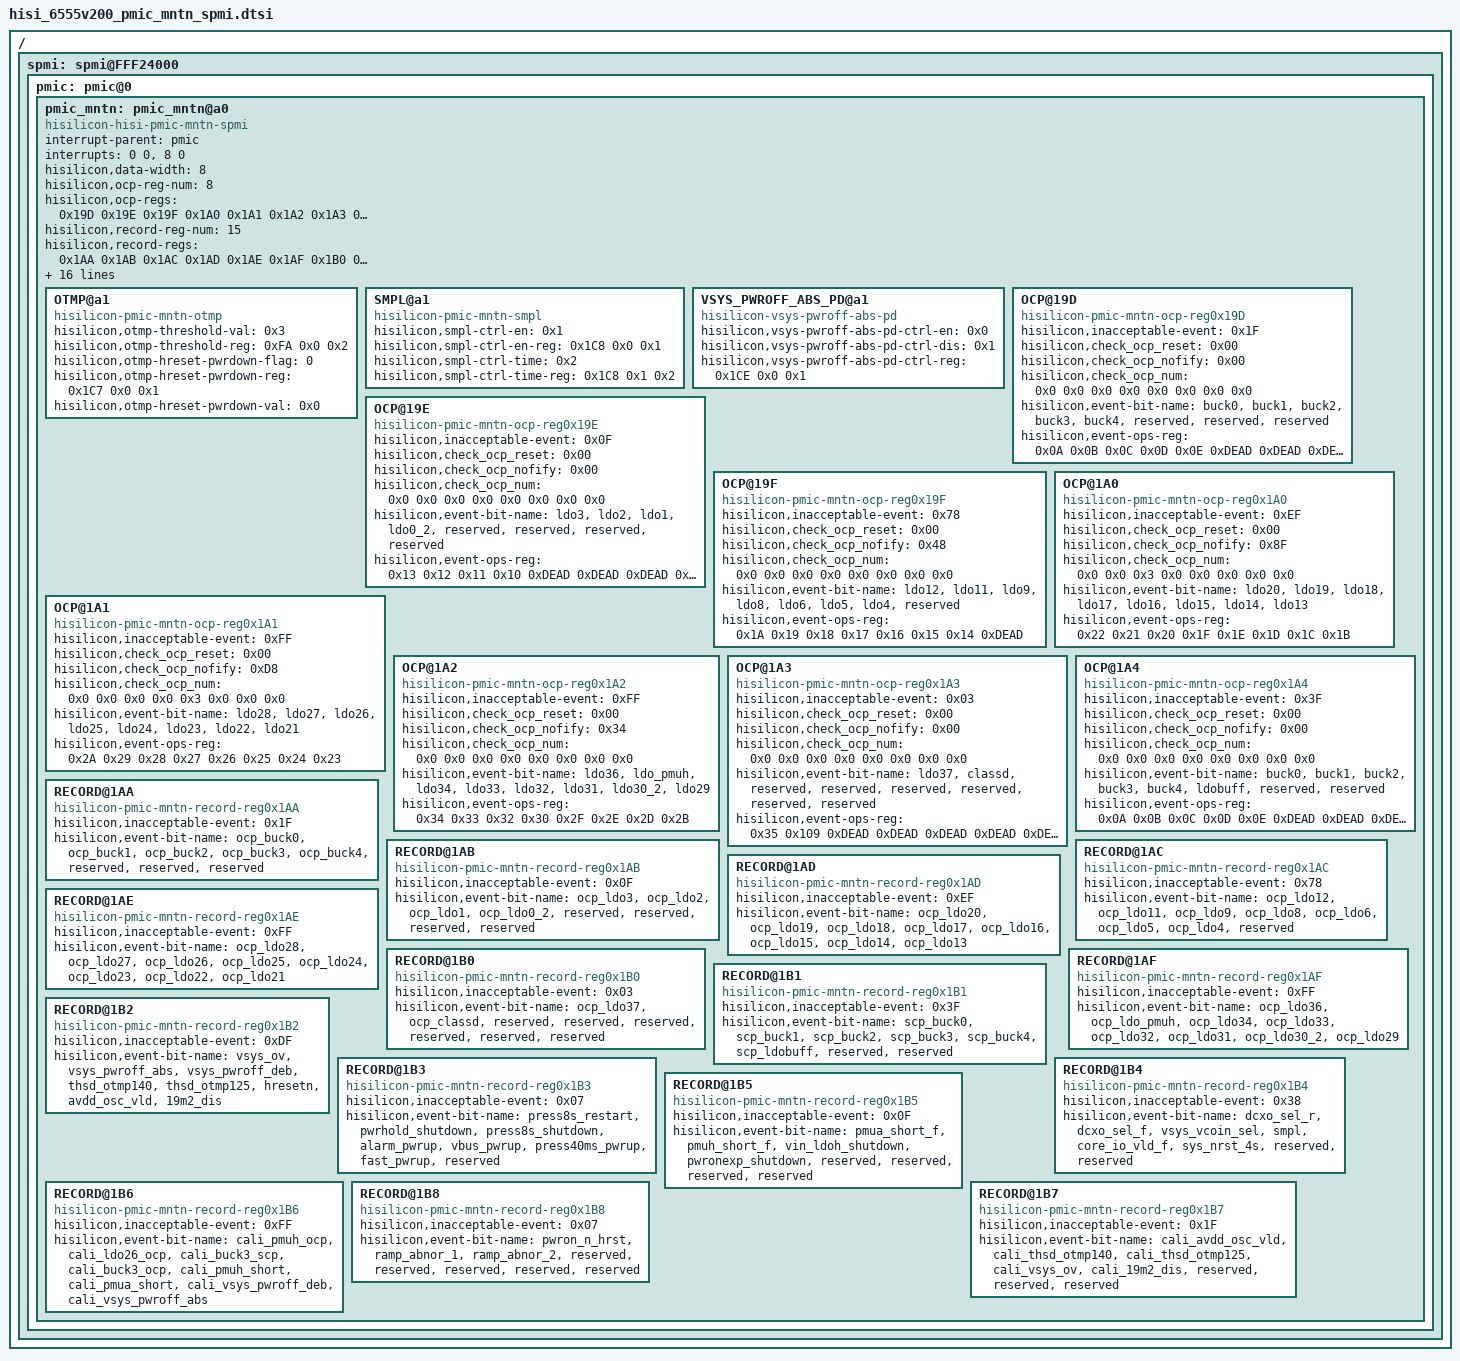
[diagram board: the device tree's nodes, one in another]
/******************************************************************************

                  版权所有 (C), 2001-2011, 华为技术有限公司

 ******************************************************************************

  This is an AUTO GENERATED file ! DON'T MODIFY MANUAL!
  文 件 名   : %(filename)s
  生成日期   : %(year)d年%(month)d月%(day)d日

******************************************************************************/

/ {
	spmi: spmi@FFF24000 {
		pmic: pmic@0 {
			pmic_mntn: pmic_mntn@a0 {
				compatible = "hisilicon-hisi-pmic-mntn-spmi";
				interrupt-parent = <&pmic>;
				interrupts = <0 0>, <8 0>;
				interrupt-names = "otmp", "ocp";
				hisilicon,data-width = <8>;
				hisilicon,ocp-reg-num = <8>;
				hisilicon,ocp-regs = <0x19D 0x19E 0x19F 0x1A0 0x1A1 0x1A2 0x1A3 0x1A4>;
				hisilicon,record-reg-num = <15>;
				hisilicon,record-regs = <0x1AA 0x1AB 0x1AC 0x1AD 0x1AE 0x1AF 0x1B0 0x1B1 0x1B2 0x1B3 0x1B4 0x1B5 0x1B6 0x1B7 0x1B8>;
				hisilicon,ocp-error-dmd-offset-number = <64>;
				hisilicon,ocp-error-dmd-offset = <
							7  6  5  4  3  99 99 99
							15 0  1  2  99 99 99 99
							23 8  10 11 50 13 14 99
							16 17 59 18 19 20 21 22
							24 25 26 27 28 29 30 31
							51 60 34 35 36 37 38 39
							61 32 99 99 99 99 99 99
							44 43 42 41 40 58 99 99
							>;
				/* this para is up to PDU, for different products may have different values */
				hisilicon,dsm-record-regs-mask = <0xFF 0xFF 0xFF 0xFF 0xFF 0xFF 0xFF 0xFF 0x00 0x00 0x00 0x00 0x00 0x00 0x00>;
				/* this para should be consistent with inacceptable-event when ocp happened */
				hisilicon,dsm-ocp-reset-mask = <0x1F 0x0F 0x78 0xEF 0xFF 0xFF 0x03 0x3F 0xFF 0xFF 0xFF 0xFF 0xFF 0xFF 0xFF>;
				hisilicon,ocp-mold-set-switch = <0>;
				hisilicon,ocp-ctrl-num = <14>;
				hisilicon,ocp-ctrl-regs = <0xDD 0xDE 0xDF 0xE0 0xE1 0xE2 0xE3 0xE4 0xE5 0xE6 0xE7 0xE8 0xE9 0xEA>;
				hisilicon,ocp-ctrl-value = <0xF7 0x03 0xDD 0x7D 0x55 0x75 0x55 0x75 0xF7 0x55 0x1F 0x07 0xF7 0x03>;
				hisilicon,pmu-record-reg-num = <7>;
				hisilicon,pmu-record-regs = <0x0EC 0x0ED 0x40 0x42 0x43 0x45 0x47>;

				OTMP@a1 {
					compatible = "hisilicon-pmic-mntn-otmp";
					/*otmp threshold value: 0x0->95, 0x1->105, 0x2->115, 0x3->125*/
					hisilicon,otmp-threshold-val = <0x3>;
					hisilicon,otmp-threshold-reg = <0xFA 0x0 0x2>;
					/*chip bug:do cold reset if pwrdown-flag == 1 && pwrdown-val == 0x0;do hot reset if pwrdown-flag == 0*/
					hisilicon,otmp-hreset-pwrdown-flag = <0>;
					hisilicon,otmp-hreset-pwrdown-reg = <0x1C7 0x0 0x1>;
					hisilicon,otmp-hreset-pwrdown-val = <0x0>;
				};

				SMPL@a1 {
					compatible = "hisilicon-pmic-mntn-smpl";
					hisilicon,smpl-ctrl-en = <0x1>;
					hisilicon,smpl-ctrl-en-reg = <0x1C8 0x0 0x1>;
					/*smpl ctrl time: 0x0->0.5s, 0x1->1.0s, 0x2->1.5s, 0x3->2.0s*/
					hisilicon,smpl-ctrl-time = <0x2>;
					hisilicon,smpl-ctrl-time-reg = <0x1C8 0x1 0x2>;
				};

				VSYS_PWROFF_ABS_PD@a1 {
					compatible = "hisilicon-vsys-pwroff-abs-pd";
					hisilicon,vsys-pwroff-abs-pd-ctrl-en = <0x0>;
					hisilicon,vsys-pwroff-abs-pd-ctrl-dis = <0x1>;
					hisilicon,vsys-pwroff-abs-pd-ctrl-reg = <0x1CE 0x0 0x1>;
				};

				OCP@19D {
					compatible = "hisilicon-pmic-mntn-ocp-reg0x19D";
					hisilicon,inacceptable-event = <0x1F>;
					hisilicon,check_ocp_reset = <0x00>;
					hisilicon,check_ocp_nofify = <0x00>;
					hisilicon,check_ocp_num = <0x0 0x0 0x0 0x0 0x0 0x0 0x0 0x0>;
					hisilicon,event-bit-name = "buck0","buck1","buck2","buck3","buck4","reserved","reserved","reserved";
					hisilicon,event-ops-reg = <0x0A 0x0B 0x0C 0x0D 0x0E 0xDEAD 0xDEAD 0xDEAD>;
				};

				OCP@19E {
					compatible = "hisilicon-pmic-mntn-ocp-reg0x19E";
					hisilicon,inacceptable-event = <0x0F>;
					hisilicon,check_ocp_reset = <0x00>;
					hisilicon,check_ocp_nofify = <0x00>;
					hisilicon,check_ocp_num = <0x0 0x0 0x0 0x0 0x0 0x0 0x0 0x0>;
					hisilicon,event-bit-name = "ldo3","ldo2","ldo1","ldo0_2","reserved","reserved","reserved","reserved";
					hisilicon,event-ops-reg = <0x13 0x12 0x11 0x10 0xDEAD 0xDEAD 0xDEAD 0xDEAD>;
				};

				OCP@19F {
					compatible = "hisilicon-pmic-mntn-ocp-reg0x19F";
					hisilicon,inacceptable-event = <0x78>;
					hisilicon,check_ocp_reset = <0x00>;
					hisilicon,check_ocp_nofify = <0x48>;
					hisilicon,check_ocp_num = <0x0 0x0 0x0 0x0 0x0 0x0 0x0 0x0>;
					hisilicon,event-bit-name = "ldo12","ldo11","ldo9","ldo8","ldo6","ldo5","ldo4","reserved";
					hisilicon,event-ops-reg = <0x1A 0x19 0x18 0x17 0x16 0x15 0x14 0xDEAD>;
				};

				OCP@1A0 {
					compatible = "hisilicon-pmic-mntn-ocp-reg0x1A0";
					hisilicon,inacceptable-event = <0xEF>;
					hisilicon,check_ocp_reset = <0x00>;
					hisilicon,check_ocp_nofify = <0x8F>;
					hisilicon,check_ocp_num = <0x0 0x0 0x3 0x0 0x0 0x0 0x0 0x0>;
					hisilicon,event-bit-name = "ldo20","ldo19","ldo18","ldo17","ldo16","ldo15","ldo14","ldo13";
					hisilicon,event-ops-reg = <0x22 0x21 0x20 0x1F 0x1E 0x1D 0x1C 0x1B>;
				};

				OCP@1A1 {
					compatible = "hisilicon-pmic-mntn-ocp-reg0x1A1";
					hisilicon,inacceptable-event = <0xFF>;
					hisilicon,check_ocp_reset = <0x00>;
					hisilicon,check_ocp_nofify = <0xD8>;
					hisilicon,check_ocp_num = <0x0 0x0 0x0 0x0 0x3 0x0 0x0 0x0>;
					hisilicon,event-bit-name = "ldo28","ldo27","ldo26","ldo25","ldo24","ldo23","ldo22","ldo21";
					hisilicon,event-ops-reg = <0x2A 0x29 0x28 0x27 0x26 0x25 0x24 0x23>;
				};

				OCP@1A2 {
					compatible = "hisilicon-pmic-mntn-ocp-reg0x1A2";
					hisilicon,inacceptable-event = <0xFF>;
					hisilicon,check_ocp_reset = <0x00>;
					hisilicon,check_ocp_nofify = <0x34>;
					hisilicon,check_ocp_num = <0x0 0x0 0x0 0x0 0x0 0x0 0x0 0x0>;
					hisilicon,event-bit-name = "ldo36","ldo_pmuh","ldo34","ldo33","ldo32","ldo31","ldo30_2","ldo29";
					hisilicon,event-ops-reg = <0x34 0x33 0x32 0x30 0x2F 0x2E 0x2D 0x2B>;
				};

				OCP@1A3 {
					compatible = "hisilicon-pmic-mntn-ocp-reg0x1A3";
					hisilicon,inacceptable-event = <0x03>;
					hisilicon,check_ocp_reset = <0x00>;
					hisilicon,check_ocp_nofify = <0x00>;
					hisilicon,check_ocp_num = <0x0 0x0 0x0 0x0 0x0 0x0 0x0 0x0>;
					hisilicon,event-bit-name = "ldo37","classd","reserved","reserved","reserved","reserved","reserved","reserved";
					hisilicon,event-ops-reg = <0x35 0x109 0xDEAD 0xDEAD 0xDEAD 0xDEAD 0xDEAD 0xDEAD>;
				};

				OCP@1A4 {
					compatible = "hisilicon-pmic-mntn-ocp-reg0x1A4";
					hisilicon,inacceptable-event = <0x3F>;
					hisilicon,check_ocp_reset = <0x00>;
					hisilicon,check_ocp_nofify = <0x00>;
					hisilicon,check_ocp_num = <0x0 0x0 0x0 0x0 0x0 0x0 0x0 0x0>;
					hisilicon,event-bit-name = "buck0","buck1","buck2","buck3","buck4","ldobuff","reserved","reserved";
					hisilicon,event-ops-reg = <0x0A 0x0B 0x0C 0x0D 0x0E 0xDEAD 0xDEAD 0xDEAD>;
				};

				RECORD@1AA {
					compatible = "hisilicon-pmic-mntn-record-reg0x1AA";
					hisilicon,inacceptable-event = <0x1F>;
					hisilicon,event-bit-name = "ocp_buck0","ocp_buck1","ocp_buck2","ocp_buck3","ocp_buck4","reserved","reserved","reserved";
				};

				RECORD@1AB {
					compatible = "hisilicon-pmic-mntn-record-reg0x1AB";
					hisilicon,inacceptable-event = <0x0F>;
					hisilicon,event-bit-name = "ocp_ldo3","ocp_ldo2","ocp_ldo1","ocp_ldo0_2","reserved","reserved","reserved","reserved";
				};

				RECORD@1AC {
					compatible = "hisilicon-pmic-mntn-record-reg0x1AC";
					hisilicon,inacceptable-event = <0x78>;
					hisilicon,event-bit-name = "ocp_ldo12","ocp_ldo11","ocp_ldo9","ocp_ldo8","ocp_ldo6","ocp_ldo5","ocp_ldo4","reserved";
				};

				RECORD@1AD {
					compatible = "hisilicon-pmic-mntn-record-reg0x1AD";
					hisilicon,inacceptable-event = <0xEF>;
					hisilicon,event-bit-name = "ocp_ldo20","ocp_ldo19","ocp_ldo18","ocp_ldo17","ocp_ldo16","ocp_ldo15","ocp_ldo14","ocp_ldo13";
				};

				RECORD@1AE {
					compatible = "hisilicon-pmic-mntn-record-reg0x1AE";
					hisilicon,inacceptable-event = <0xFF>;
					hisilicon,event-bit-name = "ocp_ldo28","ocp_ldo27","ocp_ldo26","ocp_ldo25","ocp_ldo24","ocp_ldo23","ocp_ldo22","ocp_ldo21";
				};

				RECORD@1AF {
					compatible = "hisilicon-pmic-mntn-record-reg0x1AF";
					hisilicon,inacceptable-event = <0xFF>;
					hisilicon,event-bit-name = "ocp_ldo36","ocp_ldo_pmuh","ocp_ldo34","ocp_ldo33","ocp_ldo32","ocp_ldo31","ocp_ldo30_2","ocp_ldo29";
				};

				RECORD@1B0 {
					compatible = "hisilicon-pmic-mntn-record-reg0x1B0";
					hisilicon,inacceptable-event = <0x03>;
					hisilicon,event-bit-name = "ocp_ldo37","ocp_classd","reserved","reserved","reserved","reserved","reserved","reserved";
				};

				RECORD@1B1 {
					compatible = "hisilicon-pmic-mntn-record-reg0x1B1";
					hisilicon,inacceptable-event = <0x3F>;
					hisilicon,event-bit-name = "scp_buck0","scp_buck1","scp_buck2","scp_buck3","scp_buck4","scp_ldobuff","reserved","reserved";
				};

				RECORD@1B2 {
					compatible = "hisilicon-pmic-mntn-record-reg0x1B2";
					hisilicon,inacceptable-event = <0xDF>;
					hisilicon,event-bit-name = "vsys_ov","vsys_pwroff_abs","vsys_pwroff_deb","thsd_otmp140","thsd_otmp125","hresetn","avdd_osc_vld","19m2_dis";
				};

				RECORD@1B3 {
					compatible = "hisilicon-pmic-mntn-record-reg0x1B3";
					hisilicon,inacceptable-event = <0x07>;
					hisilicon,event-bit-name = "press8s_restart","pwrhold_shutdown","press8s_shutdown","alarm_pwrup","vbus_pwrup","press40ms_pwrup","fast_pwrup","reserved";
				};

				RECORD@1B4 {
					compatible = "hisilicon-pmic-mntn-record-reg0x1B4";
					hisilicon,inacceptable-event = <0x38>;
					hisilicon,event-bit-name = "dcxo_sel_r","dcxo_sel_f","vsys_vcoin_sel","smpl","core_io_vld_f","sys_nrst_4s","reserved","reserved";
				};

				RECORD@1B5 {
					compatible = "hisilicon-pmic-mntn-record-reg0x1B5";
					hisilicon,inacceptable-event = <0x0F>;
					hisilicon,event-bit-name = "pmua_short_f","pmuh_short_f","vin_ldoh_shutdown","pwronexp_shutdown","reserved","reserved","reserved","reserved";
				};

				RECORD@1B6 {
					compatible = "hisilicon-pmic-mntn-record-reg0x1B6";
					hisilicon,inacceptable-event = <0xFF>;
					hisilicon,event-bit-name = "cali_pmuh_ocp","cali_ldo26_ocp","cali_buck3_scp","cali_buck3_ocp","cali_pmuh_short","cali_pmua_short","cali_vsys_pwroff_deb","cali_vsys_pwroff_abs";
				};

				RECORD@1B7 {
					compatible = "hisilicon-pmic-mntn-record-reg0x1B7";
					hisilicon,inacceptable-event = <0x1F>;
					hisilicon,event-bit-name = "cali_avdd_osc_vld","cali_thsd_otmp140","cali_thsd_otmp125","cali_vsys_ov","cali_19m2_dis","reserved","reserved","reserved";
				};

				RECORD@1B8 {
					compatible = "hisilicon-pmic-mntn-record-reg0x1B8";
					hisilicon,inacceptable-event = <0x07>;
					hisilicon,event-bit-name = "pwron_n_hrst","ramp_abnor_1","ramp_abnor_2","reserved","reserved","reserved","reserved","reserved";
				};
			};
		};
	};
};
